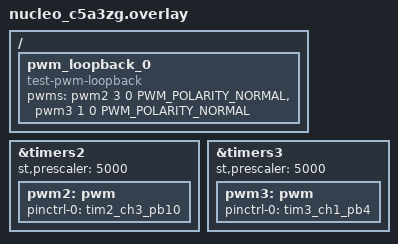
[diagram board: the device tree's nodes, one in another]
/*
 * Copyright (c) 2025 STMicroelectronics
 *
 * SPDX-License-Identifier: Apache-2.0
 */

#include <zephyr/dt-bindings/pwm/pwm.h>

/ {
	pwm_loopback_0 {
		compatible = "test-pwm-loopback";
		/* first index must be a 32-Bit timer */
		pwms = <&pwm2 3 0 PWM_POLARITY_NORMAL>,
		       <&pwm3 1 0 PWM_POLARITY_NORMAL>;
	};
};

/* 32-Bit timers */
&timers2 {
	st,prescaler = <5000>;
	status = "okay";

	pwm2: pwm {
		status = "okay";
		pinctrl-0 = <&tim2_ch3_pb10>; /* CN9 PIN7 D6 */
		pinctrl-names = "default";
	};
};

&timers3 {
	st,prescaler = <5000>;
	status = "okay";

	pwm3: pwm {
		status = "okay";
		pinctrl-0 = <&tim3_ch1_pb4>; /* CN9 PIN6 D5 */
		pinctrl-names = "default";
	};
};
